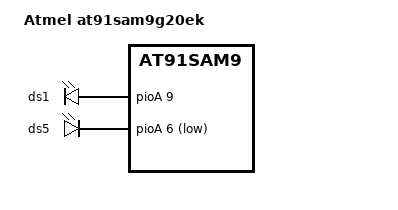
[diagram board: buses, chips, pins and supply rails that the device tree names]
// SPDX-License-Identifier: GPL-2.0-only
/*
 * at91sam9g20ek.dts - Device Tree file for Atmel at91sam9g20ek board
 *
 * Copyright (C) 2012 Jean-Christophe PLAGNIOL-VILLARD <plagnioj@jcrosoft.com>
 */
/dts-v1/;
#include "at91sam9g20ek_common.dtsi"

/ {
	model = "Atmel at91sam9g20ek";
	compatible = "atmel,at91sam9g20ek", "atmel,at91sam9g20", "atmel,at91sam9";

	leds {
		compatible = "gpio-leds";

		ds1 {
			label = "ds1";
			gpios = <&pioA 9 GPIO_ACTIVE_HIGH>;
			linux,default-trigger = "heartbeat";
		};

		ds5 {
			label = "ds5";
			gpios = <&pioA 6 GPIO_ACTIVE_LOW>;
		};
	};
};
